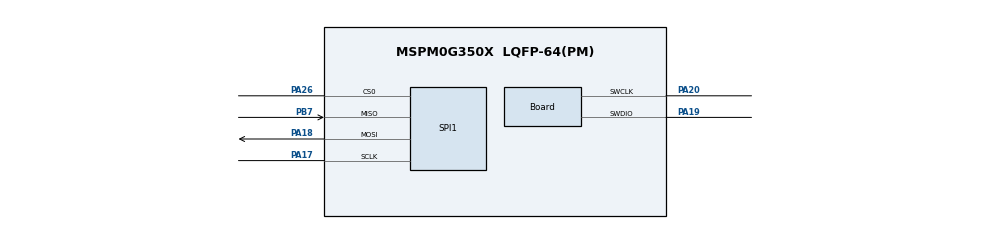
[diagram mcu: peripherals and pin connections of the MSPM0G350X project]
/**
 * @cliArgs --device "MSPM0G350X" --part "Default" --package "LQFP-64(PM)" --product "mspm0_sdk@2.02.00.05"
 * @versions {"tool":"1.21.0+3721"}
 */

/**
 * Import the modules used in this configuration.
 */
const SPI           = scripting.addModule("/ti/driverlib/SPI", {}, false);
const SPI1          = SPI.addInstance();
const SYSCTL        = scripting.addModule("/ti/driverlib/SYSCTL");
const ProjectConfig = scripting.addModule("/ti/project_config/ProjectConfig");

/**
 * Write custom configuration values to the imported modules.
 */
SPI1.$name                              = "SPI_1";
SPI1.peripheral.$assign                 = "SPI1";
SPI1.peripheral.sclkPin.$assign         = "PA17";
SPI1.peripheral.mosiPin.$assign         = "PA18";
SPI1.peripheral.misoPin.$assign         = "PB7";
SPI1.peripheral.cs0Pin.$assign          = "PA26";
SPI1.sclkPinConfig.$name                = "ti_driverlib_gpio_GPIOPinGeneric0";
SPI1.sclkPinConfig.direction            = scripting.forceWrite("OUTPUT");
SPI1.sclkPinConfig.onlyInternalResistor = scripting.forceWrite(false);
SPI1.sclkPinConfig.passedPeripheralType = scripting.forceWrite("Digital");
SPI1.mosiPinConfig.$name                = "ti_driverlib_gpio_GPIOPinGeneric1";
SPI1.mosiPinConfig.direction            = scripting.forceWrite("OUTPUT");
SPI1.mosiPinConfig.hideOutputInversion  = scripting.forceWrite(false);
SPI1.mosiPinConfig.onlyInternalResistor = scripting.forceWrite(false);
SPI1.mosiPinConfig.passedPeripheralType = scripting.forceWrite("Digital");
SPI1.misoPinConfig.$name                = "ti_driverlib_gpio_GPIOPinGeneric2";
SPI1.misoPinConfig.onlyInternalResistor = scripting.forceWrite(false);
SPI1.misoPinConfig.passedPeripheralType = scripting.forceWrite("Digital");
SPI1.cs0PinConfig.$name                 = "ti_driverlib_gpio_GPIOPinGeneric3";
SPI1.cs0PinConfig.direction             = scripting.forceWrite("OUTPUT");
SPI1.cs0PinConfig.hideOutputInversion   = scripting.forceWrite(false);
SPI1.cs0PinConfig.onlyInternalResistor  = scripting.forceWrite(false);
SPI1.cs0PinConfig.passedPeripheralType  = scripting.forceWrite("Digital");

const Board                       = scripting.addModule("/ti/driverlib/Board", {}, false);
Board.peripheral.$assign          = "DEBUGSS";
Board.peripheral.swclkPin.$assign = "PA20";
Board.peripheral.swdioPin.$assign = "PA19";

SYSCTL.peripheral.$assign = "SYSCTL";

ProjectConfig.migrationCondition = true;
